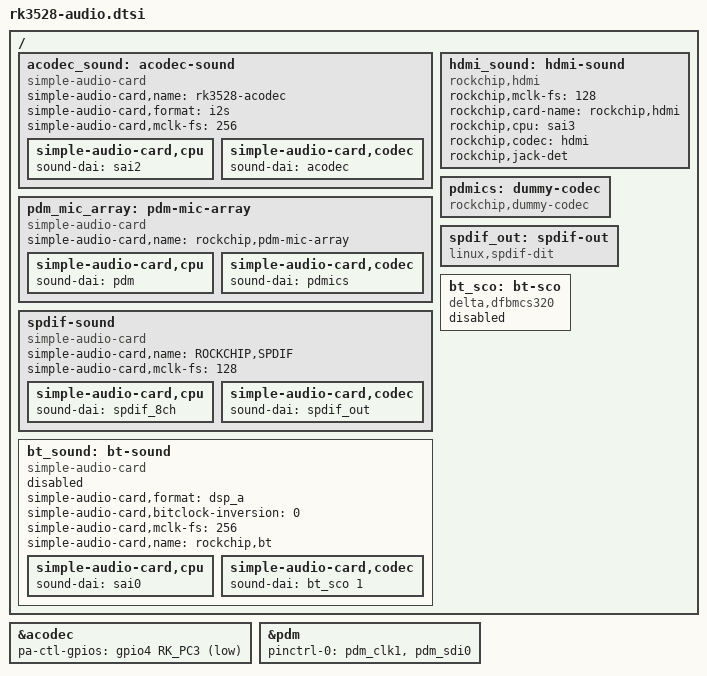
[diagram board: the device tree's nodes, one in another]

/ {
	acodec_sound: acodec-sound {
		status = "okay";
		compatible = "simple-audio-card";
		simple-audio-card,name = "rk3528-acodec";
		simple-audio-card,format = "i2s";
		simple-audio-card,mclk-fs = <256>;
		simple-audio-card,cpu {
			sound-dai = <&sai2>;
		};
		simple-audio-card,codec {
			sound-dai = <&acodec>;
		};
	};


	hdmi_sound: hdmi-sound {
		compatible = "rockchip,hdmi";
		rockchip,mclk-fs = <128>;
		rockchip,card-name = "rockchip,hdmi";
		rockchip,cpu = <&sai3>;
		rockchip,codec = <&hdmi>;
		rockchip,jack-det;
	};

	pdmics: dummy-codec {
		status = "okay";
		compatible = "rockchip,dummy-codec";
		#sound-dai-cells = <0>;
	};

	pdm_mic_array: pdm-mic-array {
		status = "okay";
		compatible = "simple-audio-card";
		simple-audio-card,name = "rockchip,pdm-mic-array";
		simple-audio-card,cpu {
			sound-dai = <&pdm>;
		};
		simple-audio-card,codec {
			sound-dai = <&pdmics>;
		};
	};

	spdif-sound {
		status = "okay";
		compatible = "simple-audio-card";
		simple-audio-card,name = "ROCKCHIP,SPDIF";
		simple-audio-card,mclk-fs = <128>;
		simple-audio-card,cpu {
			sound-dai = <&spdif_8ch>;
		};
		simple-audio-card,codec {
			sound-dai = <&spdif_out>;
		};
	};

	spdif_out: spdif-out {
		status = "okay";
		compatible = "linux,spdif-dit";
		#sound-dai-cells = <0>;
	};

	bt_sco: bt-sco {
		status = "disabled";
		compatible = "delta,dfbmcs320";
		#sound-dai-cells = <1>;
	};

	bt_sound: bt-sound {
		status = "disabled";
		compatible = "simple-audio-card";
		simple-audio-card,format = "dsp_a";
		simple-audio-card,bitclock-inversion = <0>;
		simple-audio-card,mclk-fs = <256>;
		simple-audio-card,name = "rockchip,bt";
		simple-audio-card,cpu {
			sound-dai = <&sai0>;
		};
		simple-audio-card,codec {
			sound-dai = <&bt_sco 1>;
		};
	};
};


&acodec {
	pa-ctl-gpios = <&gpio4 RK_PC3 GPIO_ACTIVE_LOW>;
	status = "okay";
};

&pdm {
	pinctrl-0 = <&pdm_clk1
        	     &pdm_sdi0>;
	status = "okay";
};
